# D1H.pdf register map
Vendor: Allwinner; Series: D1H.pdf; File version: 0.1
CPU: XuanTie C906 RISC-V CPU 0, little endian, MPU, FPU, double-precision FPU, 0 interrupt priority bits
Registers are 32-bit, read-write, reset 0x0 unless marked. A register's access mark holds for its fields unless they carry their own. Offsets are from the block's base; [hi:lo] are bit positions; {n}, {i} and the like mark numbered series.

## OWA
Base 0x02036000
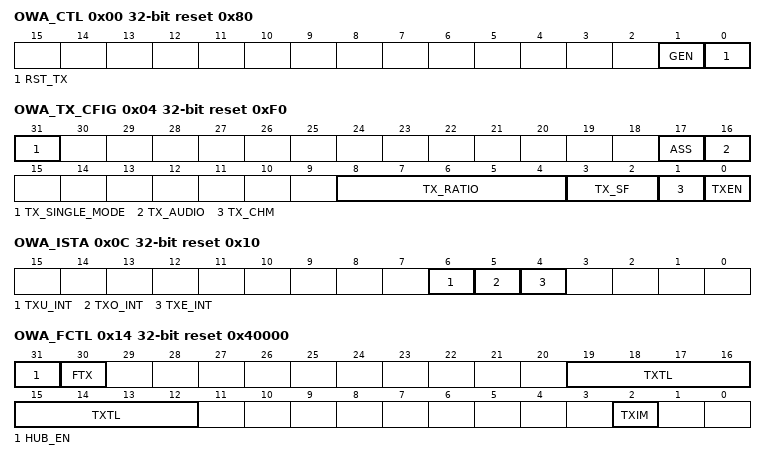
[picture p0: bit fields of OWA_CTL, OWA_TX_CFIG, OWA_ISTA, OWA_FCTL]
0x00 OWA_CTL reset 0x80
  [1] GEN — Global Enable Disabling this bit overrides the operations of enabling and flushing all FIFOs by any other blocks or channels. 0: Disabled 1: Enabled
    0=Disabled; 1=Enabled
  [0] RST_TX — Reset TX 0: Normal 1: Reset Self clear to 0.
    0=Normal; 1=Reset Self clear to 0
0x04 OWA_TX_CFIG reset 0xF0 — OWA TX Configuration Register
  [31] TX_SINGLE_MODE — Tx Single Channel Mode 0: Disabled 1: Enabled
    0=Disabled; 1=Enabled
  [17] ASS — Audio Sample Select when TX FIFO Underrun 0: Sending 0 1: Sending the last audio Note: This bit is only valid in PCM mode.
    0=Sending_0; 1=Sending the last audio Note: This bit is only valid in PCM mode
  [16] TX_AUDIO — TX Data Type 0: Linear PCM (Valid bit of both sub-frame set to 0 ) 1: Non-audio (Valid bit of both sub-frame set to 1)
    0=Linear PCM (Valid bit of both sub-frame set to 0 ); 1=Non-audio (Valid bit of both sub-frame set to 1)
  [8:4] TX_RATIO — TX Clock Divide Ratio Clock divide ratio = TX_TATIO + 1 Fs = PLL_AUDIO/[(TX_TATIO + 1)*64*2]
  [3:2] TX_SF — TX Sample Format 00: 16 bits 01: 20 bits 10: 24 bits 11: Reserved
    0=_16_bits; 1=_20_bits; 2=_24_bits
  [1] TX_CHM — CHSTMODE 0: Channel status A and B set to 0 1: Channel status A and B generated from TX_CHSTA
    0=Channel status A and B set to 0; 1=Channel status A and B generated from TX_CHSTA
  [0] TXEN — TX Enable 0: Disabled 1: Enabled
    0=Disabled; 1=Enabled
0x0C OWA_ISTA reset 0x10 — OWA Interrupt Status Register
  [6] TXU_INT write-1-clears — TX FIFO Underrun Pending Interrupt 0: No Pending IRQ 1: FIFO Underrun Pending Interrupt Writing “1” to clear this interrupt.
    0=No Pending IRQ; 1=FIFO (FIFO Underrun Pending Interrupt Writing “1” to clear this interrupt.)
  [5] TXO_INT write-1-clears — TX FIFO Overrun Pending Interrupt 0: No Pending IRQ 1: FIFO Overrun Pending Interrupt Writing “1” to clear this interrupt.
    0=No Pending IRQ; 1=FIFO (FIFO Overrun Pending Interrupt Writing “1” to clear this interrupt.)
  [4] TXE_INT write-1-clears — TX FIFO Empty Pending Interrupt 0: No Pending IRQ 1: FIFO Empty Pending Interrupt Writing “1” to clear this interrupt or automatically clear if the interrupt condition fails.
    0=No Pending IRQ; 1=FIFO (FIFO Empty Pending Interrupt Writing “1” to clear this interrupt or automatically clear if the interrupt condition fails.)
0x14 OWA_FCTL reset 0x40000 — OWA FIFO Control Register
  [31] HUB_EN — Audio Hub Enable The bit takes effect only when the TXEN is set to 1. Audio codec/I2S0/I2S1/I2S2/OWA TXFIFO Hub Enable. 0: Disabled 1: Enabled
    0=Disabled; 1=Enabled
  [30] FTX write-1-clears — Write ‘1’ to flush TXFIFO, self clear to ‘0’.
  [19:12] TXTL — TX FIFO Empty Trigger Level Interrupt and DMA request trigger level for TX FIFO normal condition. Trigger Level = TXTL
  [2] TXIM — TXFIFO Input Mode (Mode0, 1) 0: Valid data at the MSB of TXFIFO Register 1: Valid data at the LSB of TXFIFO Register Example for 20-bit transmitted audio sample: Mode 0: TXFIFO[23:0] = {APB_WDATA[31:12], 4’h0} Mode 1: TXFIFO[23:0] = {APB_WDATA[19:0], 4’h0}
    0=Valid data at the MSB of TXFIFO Register; 1=Valid data at the LSB of TXFIFO Register Example for 20-bit transmitted audio sample: Mode 0: TXFIFO[23:0] = {APB_WDATA[31:12], 4’h0} Mode 1: TXFIFO[23:0] = {APB_WDATA[19:0], 4’h0}
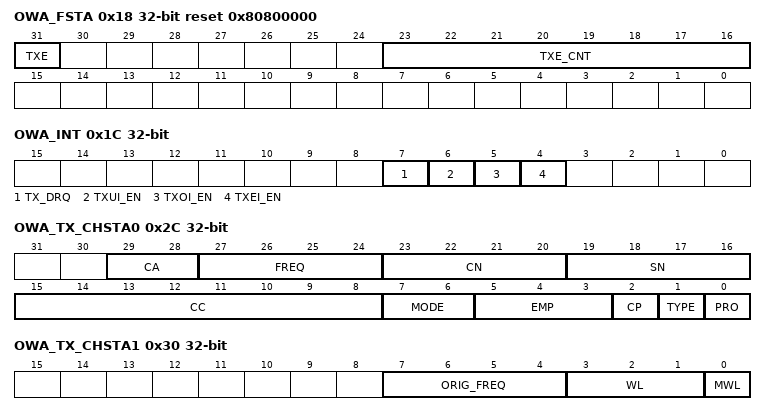
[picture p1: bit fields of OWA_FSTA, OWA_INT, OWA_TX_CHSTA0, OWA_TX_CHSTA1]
0x18 OWA_FSTA reset 0x80800000 — OWA FIFO Status Register
  [31] TXE ro — TXFIFO Empty (indicate the TXFIFO is not full) 0: No room for new sample in TXFIFO 1: More than one room for new sample in TXFIFO ( >= 1 Word )
    0=No room for new sample in TXFIFO; 1=More than one room for new sample in TXFIFO ( >= 1 Word )
  [23:16] TXE_CNT ro — TXFIFO Empty Space Word Counter
0x1C OWA_INT — OWA Interrupt Control Register
  [all] fields
    0=Disabled; 1=Enabled
  [7] TX_DRQ — TXFIFO Empty DRQ Enable 0: Disabled 1: Enabled
  [6] TXUI_EN — TXFIFO Underrun Interrupt Enable 0: Disabled 1: Enabled
  [5] TXOI_EN — TXFIFO Overrun Interrupt Enable 0: Disabled 1: Enabled
  [4] TXEI_EN — TXFIFO Empty Interrupt Enable 0: Disabled 1: Enabled
0x20 OWA_TXFIFO
  [31:0] TX_DATA wo — Transmitting A, B channel data should be written this register one by one. A channel data is first, and then the B channel data.
0x24 OWA_TX_CNT — OWA TX Counter Register
  [31:0] TX_CNT — TX Sample Counter The audio sample number of sending into TXFIFO. When one sample is put into TXFIFO by DMA or by host IO, the TX sample counter register increases by one. The TX sample counter register can be set to any initial value at any time. After updated by the initial value, the counter register should count on the base of this initial value.
0x2C OWA_TX_CHSTA0 — OWA TX Channel Status Register0
  [29:28] CA — Clock Accuracy 00: Level 2 01: Level 1 10: Level 3 11: Not matched
    0=Level_2; 1=Level_1; 2=Level_3; 3=Not_matched
  [27:24] FREQ — Sampling Frequency 0000: 44.1 kHz 0001: Not indicated 0010: 48 kHz 0011: 32 kHz 0100: 22.05 kHz 0101: Reserved 0110: 24 kHz 0111: Reserved 1000: Reserved 1001: 768 kHz 1010: 96 kHz 1011: Reserved 1100: 176.4 kHz 1101: Reserved 1110: 192 kHz 1111: Reserved
    0=_44_point_1_kHz (44.1 kHz); 1=Not_indicated; 2=_48_kHz; 3=_32_kHz; 4=_22_point_05_kHz (22.05 kHz); 6=_24_kHz; 9=_768_kHz; 10=_96_kHz; 12=_176_point_4_kHz (176.4 kHz); 14=_192_kHz
  [23:20] CN — Channel Number
  [19:16] SN — Source Number
  [15:8] CC — Category Code Indicates the kind of equipment that generates the digital audio interface signal.
  [7:6] MODE — Mode 00: Default Mode 01 to 11: Reserved
    0=Default Mode 01 to 11: Reserved
  [5:3] EMP — Emphasis Additional format information For bit 1 = “0”, Linear PCM audio mode: 000: 2 audio channels without pre-emphasis 001: 2 audio channels with 50 μs/15 μs pre-emphasis 010: Reserved (for 2 audio channels with pre-emphasis) 011: Reserved (for 2 audio channels with pre-emphasis) 100 to 111: Reserved For bit 1 = “1”, other than Linear PCM applications: 000: Default state 001 to 111: Reserved
  [2] CP — Copyright 0: Copyright is asserted 1: No copyright is asserted
    0=Copyright is asserted; 1=No copyright is asserted
  [1] TYPE — Audio Data Type 0: Linear PCM samples 1: Non-linear PCM audio
    0=Linear PCM samples; 1=Non-linear PCM audio
  [0] PRO — Application Type 0: Consumer application 1: Professional application This bit must be fixed to “0”.
    0=Consumer application; 1=Professional application This bit must be fixed to “0”
0x30 OWA_TX_CHSTA1 — OWA TX Channel Status Register1
  [7:4] ORIG_FREQ — Original Sampling Frequency 0000: Not indicated 0001: 192 kHz 0010: 12 kHz 0011: 176.4 kHz 0100: Reserved 0101: 96 kHz 0110: 8 kHz 0111: 88.2 kHz 1000: 16 kHz 1001: 24 kHz 1010: 11.025 kHz 1011: 22.05 kHz 1100: 32 kHz 1101: 48 kHz 1110: Reserved 1111: 44.1 kHz
    0=Not_indicated; 1=_192_kHz; 2=_12_kHz; 3=_176_point_4_kHz (176.4 kHz); 5=_96_kHz; 6=_8_kHz; 7=_88_point_2_kHz (88.2 kHz); 8=_16_kHz; 9=_24_kHz; 10=_11_point_025_kHz (11.025 kHz); 11=_22_point_05_kHz (22.05 kHz); 12=_32_kHz; 13=_48_kHz; 15=_44_point_1_kHz (44.1 kHz)
  [3:1] WL — Sample Word Length For bit 0 = “0”: 000: Not indicated 001: 16 bits 010: 18 bits 100: 19 bits 101: 20 bits 110: 17 bits 111: Reserved For bit 0 = “1”: 000: Not indicated 001: 20 bits 010: 22 bits 100: 23 bits 101: 24 bits 110: 21 bits 111: Reserved
  [0] MWL — Max Word Length 0: Maximum audio sample word length is 20 bits 1: Maximum audio sample word length is 24 bits
    0=Maximum audio sample word length is 20 bits; 1=Maximum audio sample word length is 24 bits
